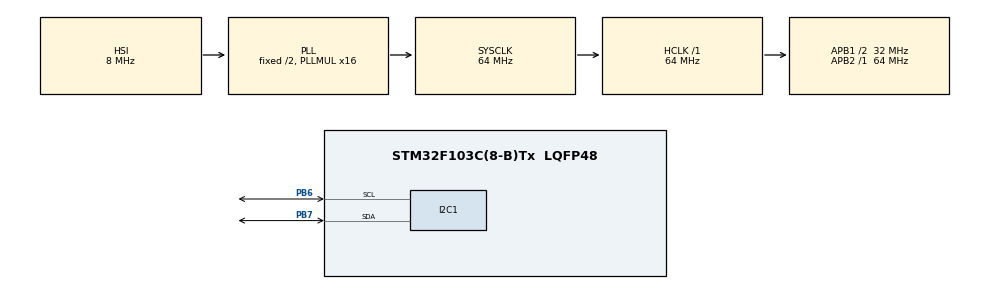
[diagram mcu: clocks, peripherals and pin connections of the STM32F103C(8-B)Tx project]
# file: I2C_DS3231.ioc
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Mcu.Family=STM32F1
Mcu.Name=STM32F103C(8-B)Tx
Mcu.Package=LQFP48
NVIC.PriorityGroup=NVIC_PRIORITYGROUP_4
PA13.Mode=Serial_Wire
PA13.Signal=SYS_JTMS-SWDIO
PA14.Mode=Serial_Wire
PA14.Signal=SYS_JTCK-SWCLK
PB6.Mode=I2C
PB6.Signal=I2C1_SCL
PB7.Mode=I2C
PB7.Signal=I2C1_SDA
PD0-OSC_IN.Mode=HSE-External-Oscillator
PD0-OSC_IN.Signal=RCC_OSC_IN
PD1-OSC_OUT.Mode=HSE-External-Oscillator
PD1-OSC_OUT.Signal=RCC_OSC_OUT
ProjectManager.HeapSize=0x200
ProjectManager.StackSize=0x400
ProjectManager.TargetToolchain=STM32CubeIDE
RCC.AHBFreq_Value=64000000
RCC.APB1CLKDivider=RCC_HCLK_DIV2
RCC.APB1Freq_Value=32000000
RCC.APB1TimFreq_Value=64000000
RCC.APB2Freq_Value=64000000
RCC.APB2TimFreq_Value=64000000
RCC.HCLKFreq_Value=64000000
RCC.PLLMUL=RCC_PLL_MUL16
RCC.SYSCLKFreq_VALUE=64000000
RCC.SYSCLKSource=RCC_SYSCLKSOURCE_PLLCLK
RCC.USBFreq_Value=64000000
board=custom

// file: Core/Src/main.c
/* USER CODE BEGIN Header */
/**
  ******************************************************************************
  * @file           : main.c
  * @brief          : Main program body
  ******************************************************************************
  * @attention
  *
  * Copyright (c) 2025 STMicroelectronics.
  * All rights reserved.
  *
  * This software is licensed under terms that can be found in the LICENSE file
  * in the root directory of this software component.
  * If no LICENSE file comes with this software, it is provided AS-IS.
  *
  ******************************************************************************
  */
/* USER CODE END Header */
#include "main.h"

/* USER CODE BEGIN Includes */

#include <stdio.h>
#include <string.h>

/* USER CODE END Includes */

/* USER CODE BEGIN PD */

#define ADDRESS_DEVICE 0x68 << 1

/* USER CODE END PD */

 I2C_HandleTypeDef hi2c1;

void SystemClock_Config(void);
static void MX_GPIO_Init(void);
static void MX_I2C1_Init(void);

/* USER CODE BEGIN 0 */

char temperature[8];

typedef struct
{
	uint8_t sec;
	uint8_t min;
	uint8_t hour;
	uint8_t day;
	uint8_t date;
	uint8_t month;
	uint8_t year;

} __attribute__((packed)) DateTime;

DateTime date_time;

uint8_t Decimal2BCD(uint8_t num)
{
    return (num / 10) << 4 | (num % 10);
}

uint8_t BCD2Decimal(uint8_t num)
{
    return (num >> 4) * 10 + (num & 0x0F);
}

void RTC_WRITE_TIME(DateTime *pDt)
{
	uint8_t data_buff[8];
	data_buff [0] = 0x00;
	data_buff [1] = Decimal2BCD(pDt->sec);
	data_buff [2] = Decimal2BCD(pDt->min);
	data_buff [3] = Decimal2BCD(pDt->hour);
	data_buff [4] = Decimal2BCD(pDt->day);
	data_buff [5] = Decimal2BCD(pDt->date);
	data_buff [6] = Decimal2BCD(pDt->month);
	data_buff [7] = Decimal2BCD(pDt->year);
	HAL_I2C_Master_Transmit(&hi2c1, ADDRESS_DEVICE, data_buff, sizeof(data_buff), 100);
}

char* RTC_READ_TEMP()
{
    static char temp_str[16];
    uint8_t add_reg = 0x11;
    uint8_t data_buff[2];

    if (HAL_I2C_Master_Transmit(&hi2c1, ADDRESS_DEVICE, &add_reg, 1, 100) != HAL_OK)
    {
        strcpy(temp_str, "ERR_TX");
        return temp_str;
    }

    if (HAL_I2C_Master_Receive(&hi2c1, ADDRESS_DEVICE, data_buff, 2, 100) != HAL_OK)
    {
        strcpy(temp_str, "ERR_RX");
        return temp_str;
    }

    int8_t temp_int = data_buff[0];
    uint8_t frac_bits = data_buff[1] >> 6;
    int frac_val = frac_bits * 25;

    sprintf(temp_str, "%d.%02dC", temp_int, frac_val);
    return temp_str;
}

void RTC_READ_TIME(DateTime *pDt)
{
	uint8_t add_reg = 0x00;
	uint8_t data_buff[7];
	HAL_I2C_Master_Transmit(&hi2c1, ADDRESS_DEVICE, &add_reg, sizeof(add_reg), 100);
	HAL_I2C_Master_Receive(&hi2c1, ADDRESS_DEVICE, data_buff, sizeof(data_buff), 100);
	pDt->sec = BCD2Decimal(data_buff [0]);
	pDt->min = BCD2Decimal(data_buff [1]);
	pDt->hour = BCD2Decimal(data_buff [2]);
	pDt->day = BCD2Decimal(data_buff [3]);
	pDt->date = BCD2Decimal(data_buff [4]);
	pDt->month = BCD2Decimal(data_buff [5]);
	pDt->year = BCD2Decimal(data_buff [6]);
}

/* USER CODE END 0 */

int main(void)
{

  /* MCU Configuration--------------------------------------------------------*/

  /* Reset of all peripherals, Initializes the Flash interface and the Systick. */
  HAL_Init();

  /* Configure the system clock */
  SystemClock_Config();

  /* Initialize all configured peripherals */
  MX_GPIO_Init();
  MX_I2C1_Init();
  /* USER CODE BEGIN 2 */

//  date_time.sec = 0;
//  date_time.min = 22;
//  date_time.hour = 23;
//  date_time.day= 2;
//  date_time.date = 16;
//  date_time.month = 6;
//  date_time.year = 25;
//  RTC_WRITE_TIME(&date_time);

  /* USER CODE END 2 */

  /* Infinite loop */
  while (1)
  {

    /* USER CODE BEGIN 3 */
	  static uint32_t time_read = 0;
	  if (HAL_GetTick() - time_read >= 1000)
	  {
		  time_read = HAL_GetTick();
		  RTC_READ_TIME(&date_time);
		  strcpy(temperature, RTC_READ_TEMP(&date_time));

	  }
  }
  /* USER CODE END 3 */
}

void SystemClock_Config(void)
{
  RCC_OscInitTypeDef RCC_OscInitStruct = {0};
  RCC_ClkInitTypeDef RCC_ClkInitStruct = {0};

  /** Initializes the RCC Oscillators according to the specified parameters
  * in the RCC_OscInitTypeDef structure.
  */
  RCC_OscInitStruct.OscillatorType = RCC_OSCILLATORTYPE_HSI;
  RCC_OscInitStruct.HSIState = RCC_HSI_ON;
  RCC_OscInitStruct.HSICalibrationValue = RCC_HSICALIBRATION_DEFAULT;
  RCC_OscInitStruct.PLL.PLLState = RCC_PLL_ON;
  RCC_OscInitStruct.PLL.PLLSource = RCC_PLLSOURCE_HSI_DIV2;
  RCC_OscInitStruct.PLL.PLLMUL = RCC_PLL_MUL16;
  if (HAL_RCC_OscConfig(&RCC_OscInitStruct) != HAL_OK)
  {
    Error_Handler();
  }

  /** Initializes the CPU, AHB and APB buses clocks
  */
  RCC_ClkInitStruct.ClockType = RCC_CLOCKTYPE_HCLK|RCC_CLOCKTYPE_SYSCLK
                              |RCC_CLOCKTYPE_PCLK1|RCC_CLOCKTYPE_PCLK2;
  RCC_ClkInitStruct.SYSCLKSource = RCC_SYSCLKSOURCE_PLLCLK;
  RCC_ClkInitStruct.AHBCLKDivider = RCC_SYSCLK_DIV1;
  RCC_ClkInitStruct.APB1CLKDivider = RCC_HCLK_DIV2;
  RCC_ClkInitStruct.APB2CLKDivider = RCC_HCLK_DIV1;

  if (HAL_RCC_ClockConfig(&RCC_ClkInitStruct, FLASH_LATENCY_2) != HAL_OK)
  {
    Error_Handler();
  }
}

static void MX_I2C1_Init(void)
{

  hi2c1.Instance = I2C1;
  hi2c1.Init.ClockSpeed = 100000;
  hi2c1.Init.DutyCycle = I2C_DUTYCYCLE_2;
  hi2c1.Init.OwnAddress1 = 0;
  hi2c1.Init.AddressingMode = I2C_ADDRESSINGMODE_7BIT;
  hi2c1.Init.DualAddressMode = I2C_DUALADDRESS_DISABLE;
  hi2c1.Init.OwnAddress2 = 0;
  hi2c1.Init.GeneralCallMode = I2C_GENERALCALL_DISABLE;
  hi2c1.Init.NoStretchMode = I2C_NOSTRETCH_DISABLE;
  if (HAL_I2C_Init(&hi2c1) != HAL_OK)
  {
    Error_Handler();
  }

}

static void MX_GPIO_Init(void)
{

  /* GPIO Ports Clock Enable */
  __HAL_RCC_GPIOD_CLK_ENABLE();
  __HAL_RCC_GPIOA_CLK_ENABLE();
  __HAL_RCC_GPIOB_CLK_ENABLE();

}

void Error_Handler(void)
{
  __disable_irq();
  while (1)
  {
  }
}
